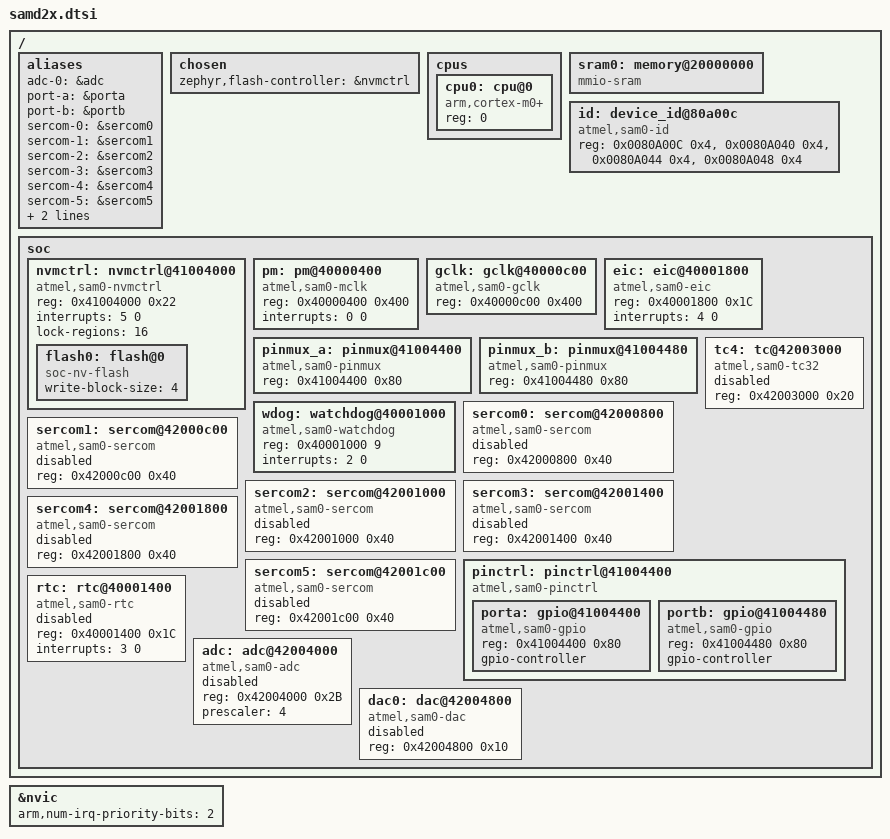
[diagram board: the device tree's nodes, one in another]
/*
 * Copyright (c) 2017 Google LLC.
 * Copyright (c) 2024 Gerson Fernando Budke <nandojve@gmail.com>
 *
 * SPDX-License-Identifier: Apache-2.0
 */

#include <mem.h>
#include <arm/armv6-m.dtsi>
#include <zephyr/dt-bindings/adc/adc.h>
#include <zephyr/dt-bindings/gpio/gpio.h>
#include <zephyr/dt-bindings/i2c/i2c.h>
#include <zephyr/dt-bindings/pwm/pwm.h>

/ {
	aliases {
		adc-0 = &adc;

		port-a = &porta;
		port-b = &portb;

		sercom-0 = &sercom0;
		sercom-1 = &sercom1;
		sercom-2 = &sercom2;
		sercom-3 = &sercom3;
		sercom-4 = &sercom4;
		sercom-5 = &sercom5;

		tc-4 = &tc4;

		watchdog0 = &wdog;
	};

	chosen {
		zephyr,flash-controller = &nvmctrl;
	};

	cpus {
		#address-cells = <1>;
		#size-cells = <0>;

		cpu0: cpu@0 {
			compatible = "arm,cortex-m0+";
			reg = <0>;

			device_type = "cpu";
		};
	};

	sram0: memory@20000000 {
		compatible = "mmio-sram";
	};

	id: device_id@80a00c {
		compatible = "atmel,sam0-id";
		reg =	<0x0080A00C 0x4>,
			<0x0080A040 0x4>,
			<0x0080A044 0x4>,
			<0x0080A048 0x4>;
	};

	soc {
		nvmctrl: nvmctrl@41004000  {
			compatible = "atmel,sam0-nvmctrl";
			reg = <0x41004000 0x22>;
			interrupts = <5 0>;

			#address-cells = <1>;
			#size-cells = <1>;

			lock-regions = <16>;

			flash0: flash@0 {
				compatible = "soc-nv-flash";

				write-block-size = <4>;
			};
		};

		pm: pm@40000400 {
			compatible = "atmel,sam0-mclk";
			reg = <0x40000400 0x400>;
			interrupts = <0 0>;

			#clock-cells = <2>;
		};

		gclk: gclk@40000c00 {
			compatible = "atmel,sam0-gclk";
			reg = <0x40000c00 0x400>;

			#clock-cells = <1>;
			#atmel,assigned-clock-cells = <1>;
		};

		eic: eic@40001800 {
			compatible = "atmel,sam0-eic";
			reg = <0x40001800 0x1C>;
			interrupts = <4 0>;
		};

		pinmux_a: pinmux@41004400 {
			compatible = "atmel,sam0-pinmux";
			reg = <0x41004400 0x80>;
		};

		pinmux_b: pinmux@41004480 {
			compatible = "atmel,sam0-pinmux";
			reg = <0x41004480 0x80>;
		};

		wdog: watchdog@40001000 {
			compatible = "atmel,sam0-watchdog";
			reg = <0x40001000 9>;
			interrupts = <2 0>;
		};

		sercom0: sercom@42000800 {
			compatible = "atmel,sam0-sercom";
			reg = <0x42000800 0x40>;
			status = "disabled";
		};

		sercom1: sercom@42000c00 {
			compatible = "atmel,sam0-sercom";
			reg = <0x42000c00 0x40>;
			status = "disabled";
		};

		sercom2: sercom@42001000 {
			compatible = "atmel,sam0-sercom";
			reg = <0x42001000 0x40>;
			status = "disabled";
		};

		sercom3: sercom@42001400 {
			compatible = "atmel,sam0-sercom";
			reg = <0x42001400 0x40>;
			status = "disabled";
		};

		sercom4: sercom@42001800 {
			compatible = "atmel,sam0-sercom";
			reg = <0x42001800 0x40>;
			status = "disabled";
		};

		sercom5: sercom@42001c00 {
			compatible = "atmel,sam0-sercom";
			reg = <0x42001c00 0x40>;
			status = "disabled";
		};

		tc4: tc@42003000 {
			compatible = "atmel,sam0-tc32";
			reg = <0x42003000 0x20>;
			status = "disabled";
		};

		pinctrl: pinctrl@41004400 {
			compatible = "atmel,sam0-pinctrl";
			ranges = <0x41004400 0x41004400 0x100>;

			#address-cells = <1>;
			#size-cells = <1>;

			porta: gpio@41004400 {
				compatible = "atmel,sam0-gpio";
				reg = <0x41004400 0x80>;

				#atmel,pin-cells = <2>;
				#gpio-cells = <2>;

				gpio-controller;
			};

			portb: gpio@41004480 {
				compatible = "atmel,sam0-gpio";
				reg = <0x41004480 0x80>;

				#atmel,pin-cells = <2>;
				#gpio-cells = <2>;

				gpio-controller;
			};
		};

		rtc: rtc@40001400 {
			compatible = "atmel,sam0-rtc";
			reg = <0x40001400 0x1C>;
			interrupts = <3 0>;
			status = "disabled";
		};

		adc: adc@42004000 {
			compatible = "atmel,sam0-adc";
			reg = <0x42004000 0x2B>;
			status = "disabled";

			#io-channel-cells = <1>;

			prescaler = <4>;
		};

		dac0: dac@42004800 {
			compatible = "atmel,sam0-dac";
			reg = <0x42004800 0x10>;
			status = "disabled";

			#io-channel-cells = <0>;
		};
	};
};

&nvic {
	arm,num-irq-priority-bits = <2>;
};
